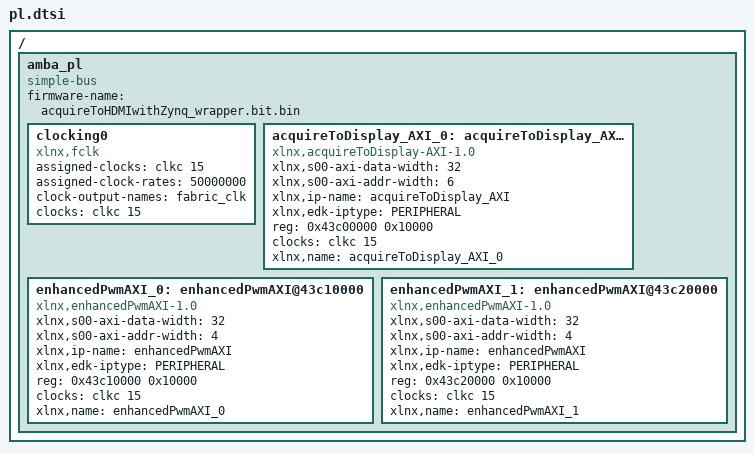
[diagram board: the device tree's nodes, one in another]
/ {
	amba_pl: amba_pl {
		ranges;
		compatible = "simple-bus";
		#address-cells = <1>;
		#size-cells = <1>;
		firmware-name = "acquireToHDMIwithZynq_wrapper.bit.bin";
		clocking0: clocking0 {
			compatible = "xlnx,fclk";
			assigned-clocks = <&clkc 15>;
			assigned-clock-rates = <50000000>;
			#clock-cells = <0>;
			clock-output-names = "fabric_clk";
			clocks = <&clkc 15>;
		};
		acquireToDisplay_AXI_0: acquireToDisplay_AXI@43c00000 {
			xlnx,s00-axi-data-width = <32>;
			compatible = "xlnx,acquireToDisplay-AXI-1.0";
			status = "okay";
			clock-names = "s00_axi_aclk";
			xlnx,s00-axi-addr-width = <6>;
			xlnx,ip-name = "acquireToDisplay_AXI";
			xlnx,edk-iptype = "PERIPHERAL";
			reg = <0x43c00000 0x10000>;
			clocks = <&clkc 15>;
			xlnx,name = "acquireToDisplay_AXI_0";
		};
		enhancedPwmAXI_0: enhancedPwmAXI@43c10000 {
			xlnx,s00-axi-data-width = <32>;
			compatible = "xlnx,enhancedPwmAXI-1.0";
			status = "okay";
			clock-names = "s00_axi_aclk";
			xlnx,s00-axi-addr-width = <4>;
			xlnx,ip-name = "enhancedPwmAXI";
			xlnx,edk-iptype = "PERIPHERAL";
			reg = <0x43c10000 0x10000>;
			clocks = <&clkc 15>;
			xlnx,name = "enhancedPwmAXI_0";
		};
		enhancedPwmAXI_1: enhancedPwmAXI@43c20000 {
			xlnx,s00-axi-data-width = <32>;
			compatible = "xlnx,enhancedPwmAXI-1.0";
			status = "okay";
			clock-names = "s00_axi_aclk";
			xlnx,s00-axi-addr-width = <4>;
			xlnx,ip-name = "enhancedPwmAXI";
			xlnx,edk-iptype = "PERIPHERAL";
			reg = <0x43c20000 0x10000>;
			clocks = <&clkc 15>;
			xlnx,name = "enhancedPwmAXI_1";
		};
	};
};
